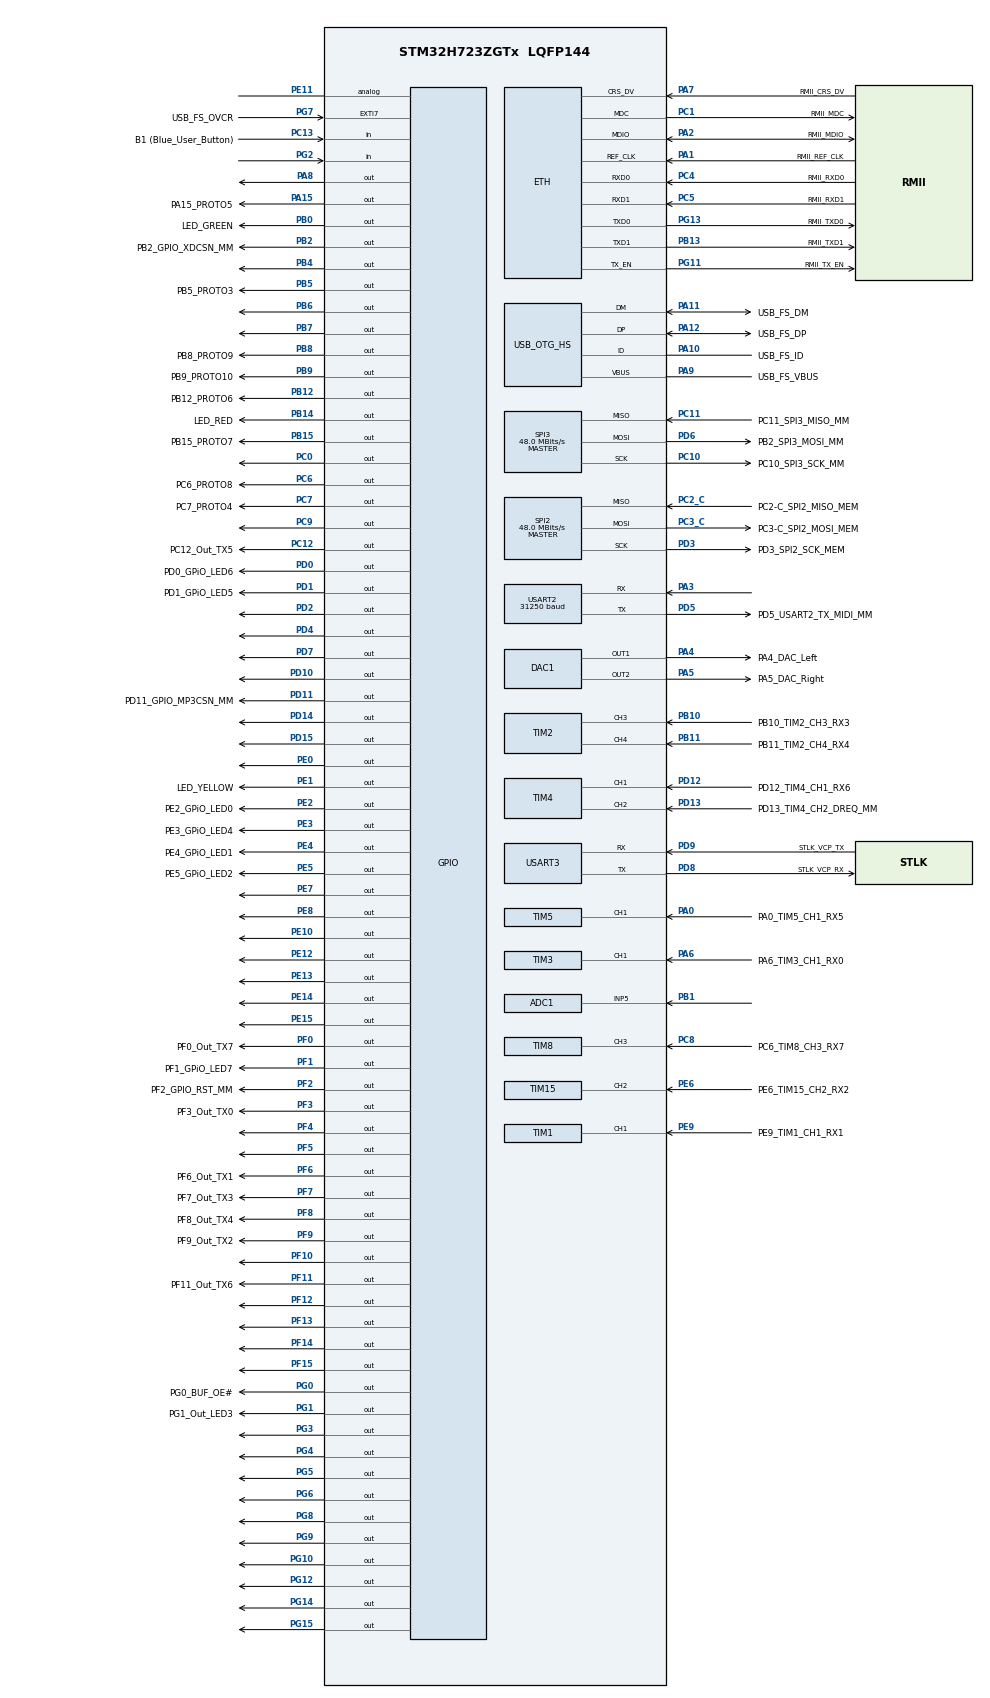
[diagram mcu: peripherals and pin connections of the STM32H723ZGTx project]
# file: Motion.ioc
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ADC1.Channel-0\#ChannelRegularConversion=ADC_CHANNEL_5
ADC1.NbrOfConversionFlag=1
ADC1.OffsetNumber-0\#ChannelRegularConversion=ADC_OFFSET_NONE
ADC1.OffsetSignedSaturation-0\#ChannelRegularConversion=DISABLE
ADC1.Rank-0\#ChannelRegularConversion=1
ADC1.SamplingTime-0\#ChannelRegularConversion=ADC_SAMPLETIME_1CYCLE_5
ADC1.master=1
DAC1.DAC_Channel-DAC_OUT1=DAC_CHANNEL_1
DAC1.DAC_Channel-DAC_OUT2=DAC_CHANNEL_2
DAC1.DAC_Trigger-DAC_OUT1=DAC_TRIGGER_T6_TRGO
DAC1.DAC_Trigger-DAC_OUT2=DAC_TRIGGER_T6_TRGO
Dma.DAC1_CH1.0.Direction=DMA_MEMORY_TO_PERIPH
Dma.DAC1_CH1.0.EventEnable=DISABLE
Dma.DAC1_CH1.0.FIFOMode=DMA_FIFOMODE_ENABLE
Dma.DAC1_CH1.0.FIFOThreshold=DMA_FIFO_THRESHOLD_FULL
Dma.DAC1_CH1.0.Instance=DMA1_Stream0
Dma.DAC1_CH1.0.MemBurst=DMA_MBURST_SINGLE
Dma.DAC1_CH1.0.MemDataAlignment=DMA_MDATAALIGN_HALFWORD
Dma.DAC1_CH1.0.MemInc=DMA_MINC_ENABLE
Dma.DAC1_CH1.0.Mode=DMA_CIRCULAR
Dma.DAC1_CH1.0.PeriphBurst=DMA_PBURST_SINGLE
Dma.DAC1_CH1.0.PeriphDataAlignment=DMA_PDATAALIGN_HALFWORD
Dma.DAC1_CH1.0.PeriphInc=DMA_PINC_DISABLE
Dma.DAC1_CH1.0.Polarity=HAL_DMAMUX_REQ_GEN_RISING
Dma.DAC1_CH1.0.Priority=DMA_PRIORITY_LOW
Dma.DAC1_CH1.0.RequestNumber=1
Dma.DAC1_CH1.0.SignalID=NONE
Dma.DAC1_CH1.0.SyncEnable=DISABLE
Dma.DAC1_CH1.0.SyncPolarity=HAL_DMAMUX_SYNC_NO_EVENT
Dma.DAC1_CH1.0.SyncRequestNumber=1
Dma.DAC1_CH1.0.SyncSignalID=NONE
Dma.DAC1_CH2.1.Direction=DMA_MEMORY_TO_PERIPH
Dma.DAC1_CH2.1.EventEnable=DISABLE
Dma.DAC1_CH2.1.FIFOMode=DMA_FIFOMODE_ENABLE
Dma.DAC1_CH2.1.FIFOThreshold=DMA_FIFO_THRESHOLD_FULL
Dma.DAC1_CH2.1.Instance=DMA1_Stream1
Dma.DAC1_CH2.1.MemBurst=DMA_MBURST_SINGLE
Dma.DAC1_CH2.1.MemDataAlignment=DMA_MDATAALIGN_HALFWORD
Dma.DAC1_CH2.1.MemInc=DMA_MINC_ENABLE
Dma.DAC1_CH2.1.Mode=DMA_NORMAL
Dma.DAC1_CH2.1.PeriphBurst=DMA_PBURST_SINGLE
Dma.DAC1_CH2.1.PeriphDataAlignment=DMA_PDATAALIGN_HALFWORD
Dma.DAC1_CH2.1.PeriphInc=DMA_PINC_DISABLE
Dma.DAC1_CH2.1.Polarity=HAL_DMAMUX_REQ_GEN_RISING
Dma.DAC1_CH2.1.Priority=DMA_PRIORITY_LOW
Dma.DAC1_CH2.1.RequestNumber=1
Dma.DAC1_CH2.1.SignalID=NONE
Dma.DAC1_CH2.1.SyncEnable=DISABLE
Dma.DAC1_CH2.1.SyncPolarity=HAL_DMAMUX_SYNC_NO_EVENT
Dma.DAC1_CH2.1.SyncRequestNumber=1
Dma.DAC1_CH2.1.SyncSignalID=NONE
Dma.Request0=DAC1_CH1
Dma.Request1=DAC1_CH2
ETH.MediaInterface=HAL_ETH_RMII_MODE
Mcu.Family=STM32H7
Mcu.Name=STM32H723ZGTx
Mcu.Package=LQFP144
NVIC.DMA1_Stream0_IRQn=true\:0\:0\:false\:false\:true\:false\:true\:true
NVIC.DMA1_Stream1_IRQn=true\:0\:0\:false\:false\:true\:false\:true\:true
NVIC.PriorityGroup=NVIC_PRIORITYGROUP_4
NVIC.TIM6_DAC_IRQn=true\:0\:0\:false\:false\:true\:true\:true\:true
NVIC.TIM8_BRK_TIM12_IRQn=true\:15\:0\:false\:false\:true\:false\:true\:true
NVIC.TimeBase=TIM8_BRK_TIM12_IRQn
NVIC.TimeBaseIP=TIM12
PA0.GPIO_Label=PA0_TIM5_CH1_RX5
PA0.Signal=S_TIM5_CH1
PA1.GPIO_Label=RMII_REF_CLK
PA1.Mode=RMII
PA1.Signal=ETH_REF_CLK
PA10.GPIO_Label=USB_FS_ID
PA10.Mode=OTG/Dual-Role-Device-FS
PA10.Signal=USB_OTG_HS_ID
PA11.GPIO_Label=USB_FS_DM
PA11.Mode=OTG/Dual-Role-Device-FS
PA11.Signal=USB_OTG_HS_DM
PA12.GPIO_Label=USB_FS_DP
PA12.Mode=OTG/Dual-Role-Device-FS
PA12.Signal=USB_OTG_HS_DP
PA13(JTMS/SWDIO).GPIO_Label=SWDIO
PA13(JTMS/SWDIO).Mode=Trace_Asynchronous_SW
PA13(JTMS/SWDIO).Signal=DEBUG_JTMS-SWDIO
PA14(JTCK/SWCLK).GPIO_Label=SWCLK
PA14(JTCK/SWCLK).Mode=Trace_Asynchronous_SW
PA14(JTCK/SWCLK).Signal=DEBUG_JTCK-SWCLK
PA15(JTDI).GPIO_Label=PA15_PROTO5
PA15(JTDI).Signal=GPIO_Output
PA2.GPIO_Label=RMII_MDIO
PA2.Mode=RMII
PA2.Signal=ETH_MDIO
PA3.Mode=Asynchronous
PA3.Signal=USART2_RX
PA4.GPIO_Label=PA4_DAC_Left
PA4.Signal=COMP_DAC11_group
PA5.GPIO_Label=PA5_DAC_Right
PA5.Signal=COMP_DAC12_group
PA6.GPIO_Label=PA6_TIM3_CH1_RX0
PA6.Signal=S_TIM3_CH1
PA7.GPIO_Label=RMII_CRS_DV
PA7.Mode=RMII
PA7.Signal=ETH_CRS_DV
PA8.Signal=GPIO_Output
PA9.GPIO_Label=USB_FS_VBUS
PA9.Mode=Activate_VBUS_FS
PA9.Signal=USB_OTG_HS_VBUS
PB0.GPIO_Label=LED_GREEN
PB0.Signal=GPIO_Output
PB1.Signal=ADCx_INP5
PB10.GPIO_Label=PB10_TIM2_CH3_RX3
PB10.Signal=S_TIM2_CH3
PB11.GPIO_Label=PB11_TIM2_CH4_RX4
PB11.Signal=S_TIM2_CH4
PB12.GPIO_Label=PB12_PROTO6
PB12.Signal=GPIO_Output
PB13.GPIO_Label=RMII_TXD1
PB13.Mode=RMII
PB13.Signal=ETH_TXD1
PB14.GPIO_Label=LED_RED
PB14.Signal=GPIO_Output
PB15.GPIO_Label=PB15_PROTO7
PB15.Signal=GPIO_Output
PB2.GPIO_Label=PB2_GPIO_XDCSN_MM
PB2.Signal=GPIO_Output
PB3(JTDO/TRACESWO).GPIO_Label=SWO
PB3(JTDO/TRACESWO).Mode=Trace_Asynchronous_SW
PB3(JTDO/TRACESWO).Signal=DEBUG_JTDO-SWO
PB4(NJTRST).Signal=GPIO_Output
PB5.GPIO_Label=PB5_PROTO3
PB5.Signal=GPIO_Output
PB6.Signal=GPIO_Output
PB7.Signal=GPIO_Output
PB8.GPIO_Label=PB8_PROTO9
PB8.Signal=GPIO_Output
PB9.GPIO_Label=PB9_PROTO10
PB9.Signal=GPIO_Output
PC0.Signal=GPIO_Output
PC1.GPIO_Label=RMII_MDC
PC1.Mode=RMII
PC1.Signal=ETH_MDC
PC10.GPIO_Label=PC10_SPI3_SCK_MM
PC10.Mode=Full_Duplex_Master
PC10.Signal=SPI3_SCK
PC11.GPIO_Label=PC11_SPI3_MISO_MM
PC11.Mode=Full_Duplex_Master
PC11.Signal=SPI3_MISO
PC12.GPIO_Label=PC12_Out_TX5
PC12.Signal=GPIO_Output
PC13.GPIO_Label=B1 (Blue_User_Button)
PC13.Signal=GPIO_Input
PC14-OSC32_IN.Mode=LSE-External-Oscillator
PC14-OSC32_IN.Signal=RCC_OSC32_IN
PC15-OSC32_OUT.Mode=LSE-External-Oscillator
PC15-OSC32_OUT.Signal=RCC_OSC32_OUT
PC2_C.GPIO_Label=PC2-C_SPI2_MISO_MEM
PC2_C.Mode=Full_Duplex_Master
PC2_C.Signal=SPI2_MISO
PC3_C.GPIO_Label=PC3-C_SPI2_MOSI_MEM
PC3_C.Mode=Full_Duplex_Master
PC3_C.Signal=SPI2_MOSI
PC4.GPIO_Label=RMII_RXD0
PC4.Mode=RMII
PC4.Signal=ETH_RXD0
PC5.GPIO_Label=RMII_RXD1
PC5.Mode=RMII
PC5.Signal=ETH_RXD1
PC6.GPIO_Label=PC6_PROTO8
PC6.Signal=GPIO_Output
PC7.GPIO_Label=PC7_PROTO4
PC7.Signal=GPIO_Output
PC8.GPIO_Label=PC6_TIM8_CH3_RX7
PC8.Signal=S_TIM8_CH3
PC9.Signal=GPIO_Output
PD0.GPIO_Label=PD0_GPiO_LED6
PD0.Signal=GPIO_Output
PD1.GPIO_Label=PD1_GPiO_LED5
PD1.Signal=GPIO_Output
PD10.Signal=GPIO_Output
PD11.GPIO_Label=PD11_GPIO_MP3CSN_MM
PD11.Signal=GPIO_Output
PD12.GPIO_Label=PD12_TIM4_CH1_RX6
PD12.Signal=S_TIM4_CH1
PD13.GPIO_Label=PD13_TIM4_CH2_DREQ_MM
PD13.Signal=S_TIM4_CH2
PD14.Signal=GPIO_Output
PD15.Signal=GPIO_Output
PD2.Signal=GPIO_Output
PD3.GPIO_Label=PD3_SPI2_SCK_MEM
PD3.Mode=Full_Duplex_Master
PD3.Signal=SPI2_SCK
PD4.Signal=GPIO_Output
PD5.GPIO_Label=PD5_USART2_TX_MIDI_MM
PD5.Mode=Asynchronous
PD5.Signal=USART2_TX
PD6.GPIO_Label=PB2_SPI3_MOSI_MM
PD6.Mode=Full_Duplex_Master
PD6.Signal=SPI3_MOSI
PD7.Signal=GPIO_Output
PD8.GPIO_Label=STLK_VCP_RX
PD8.Mode=Asynchronous
PD8.Signal=USART3_TX
PD9.GPIO_Label=STLK_VCP_TX
PD9.Mode=Asynchronous
PD9.Signal=USART3_RX
PE0.Signal=GPIO_Output
PE1.GPIO_Label=LED_YELLOW
PE1.Signal=GPIO_Output
PE10.Signal=GPIO_Output
PE11.Signal=GPIO_Analog
PE12.Signal=GPIO_Output
PE13.Signal=GPIO_Output
PE14.Signal=GPIO_Output
PE15.Signal=GPIO_Output
PE2.GPIO_Label=PE2_GPiO_LED0
PE2.Signal=GPIO_Output
PE3.GPIO_Label=PE3_GPiO_LED4
PE3.Signal=GPIO_Output
PE4.GPIO_Label=PE4_GPiO_LED1
PE4.Signal=GPIO_Output
PE5.GPIO_Label=PE5_GPiO_LED2
PE5.Signal=GPIO_Output
PE6.GPIO_Label=PE6_TIM15_CH2_RX2
PE6.Signal=S_TIM15_CH2
PE7.Signal=GPIO_Output
PE8.Signal=GPIO_Output
PE9.GPIO_Label=PE9_TIM1_CH1_RX1
PE9.Signal=S_TIM1_CH1
PF0.GPIO_Label=PF0_Out_TX7
PF0.Signal=GPIO_Output
PF1.GPIO_Label=PF1_GPiO_LED7
PF1.Signal=GPIO_Output
PF10.Signal=GPIO_Output
PF11.GPIO_Label=PF11_Out_TX6
PF11.Signal=GPIO_Output
PF12.Signal=GPIO_Output
PF13.Signal=GPIO_Output
PF14.Signal=GPIO_Output
PF15.Signal=GPIO_Output
PF2.GPIO_Label=PF2_GPIO_RST_MM
PF2.Signal=GPIO_Output
PF3.GPIO_Label=PF3_Out_TX0
PF3.Signal=GPIO_Output
PF4.Signal=GPIO_Output
PF5.Signal=GPIO_Output
PF6.GPIO_Label=PF6_Out_TX1
PF6.Signal=GPIO_Output
PF7.GPIO_Label=PF7_Out_TX3
PF7.Signal=GPIO_Output
PF8.GPIO_Label=PF8_Out_TX4
PF8.Signal=GPIO_Output
PF9.GPIO_Label=PF9_Out_TX2
PF9.Signal=GPIO_Output
PG0.GPIO_Label=PG0_BUF_OE\#
PG0.Signal=GPIO_Output
PG1.GPIO_Label=PG1_Out_LED3
PG1.Signal=GPIO_Output
PG10.Signal=GPIO_Output
PG11.GPIO_Label=RMII_TX_EN
PG11.Mode=RMII
PG11.Signal=ETH_TX_EN
PG12.Signal=GPIO_Output
PG13.GPIO_Label=RMII_TXD0
PG13.Mode=RMII
PG13.Signal=ETH_TXD0
PG14.Signal=GPIO_Output
PG15.Signal=GPIO_Output
PG2.Signal=GPIO_Input
PG3.Signal=GPIO_Output
PG4.Signal=GPIO_Output
PG5.Signal=GPIO_Output
PG6.Signal=GPIO_Output
PG7.GPIO_Label=USB_FS_OVCR
PG7.Signal=GPXTI7
PG8.Signal=GPIO_Output
PG9.Signal=GPIO_Output
PH0-OSC_IN.GPIO_Label=MCO
PH0-OSC_IN.Mode=HSE-External-Clock-Source
PH0-OSC_IN.Signal=RCC_OSC_IN
PH1-OSC_OUT.Signal=RCC_OSC_OUT
ProjectManager.HeapSize=0x200
ProjectManager.StackSize=0x400
ProjectManager.TargetToolchain=STM32CubeIDE
RCC.ADCFreq_Value=48000000
RCC.APB1Freq_Value=48000000
RCC.APB2Freq_Value=48000000
RCC.APB3Freq_Value=48000000
RCC.APB4Freq_Value=48000000
RCC.CortexFreq_Value=192000000
RCC.D1PPRE=RCC_APB3_DIV2
RCC.D2PPRE1=RCC_APB1_DIV2
RCC.D2PPRE2=RCC_APB2_DIV2
RCC.D3PPRE=RCC_APB4_DIV2
RCC.DIVM1=1
RCC.DIVM2=1
RCC.DIVN1=24
RCC.DIVN2=24
RCC.DIVP1=1
RCC.DIVP2=4
RCC.HCLKFreq_Value=96000000
RCC.HPRE=RCC_HCLK_DIV2
RCC.HSE_VALUE=8000000
RCC.PLL2FRACN=0
RCC.PLLFRACN=0
RCC.PLLSourceVirtual=RCC_PLLSOURCE_HSE
RCC.SYSCLKFreq_VALUE=192000000
RCC.SYSCLKSource=RCC_SYSCLKSOURCE_PLLCLK
RCC.USBCLockSelection=RCC_USBCLKSOURCE_HSI48
RCC.USBFreq_Value=48000000
SH.ADCx_INP5.0=ADC1_INP5,IN5-Single-Ended
SH.COMP_DAC11_group.0=DAC1_OUT1,DAC_OUT1
SH.COMP_DAC12_group.0=DAC1_OUT2,DAC_OUT2
SH.S_TIM15_CH2.0=TIM15_CH2,Input_Capture2_from_TI2
SH.S_TIM1_CH1.0=TIM1_CH1,Input_Capture1_from_TI1
SH.S_TIM2_CH3.0=TIM2_CH3,Input_Capture3_from_TI3
SH.S_TIM2_CH4.0=TIM2_CH4,Input_Capture4_from_TI4
SH.S_TIM3_CH1.0=TIM3_CH1,Input_Capture1_from_TI1
SH.S_TIM4_CH1.0=TIM4_CH1,Input_Capture1_from_TI1
SH.S_TIM4_CH2.0=TIM4_CH2,Input_Capture2_from_TI2
SH.S_TIM5_CH1.0=TIM5_CH1,Input_Capture1_from_TI1
SH.S_TIM8_CH3.0=TIM8_CH3,Input_Capture3_from_TI3
SPI2.CalculateBaudRate=48.0 MBits/s
SPI2.Direction=SPI_DIRECTION_2LINES
SPI2.Mode=SPI_MODE_MASTER
SPI2.VirtualType=VM_MASTER
SPI3.CalculateBaudRate=48.0 MBits/s
SPI3.Direction=SPI_DIRECTION_2LINES
SPI3.Mode=SPI_MODE_MASTER
SPI3.VirtualType=VM_MASTER
TIM1.Channel-Input_Capture1_from_TI1=TIM_CHANNEL_1
TIM15.Channel-Input_Capture2_from_TI2=TIM_CHANNEL_2
TIM2.Channel-Input_Capture3_from_TI3=TIM_CHANNEL_3
TIM2.Channel-Input_Capture4_from_TI4=TIM_CHANNEL_4
TIM3.Channel-Input_Capture1_from_TI1=TIM_CHANNEL_1
TIM4.Channel-Input_Capture1_from_TI1=TIM_CHANNEL_1
TIM4.Channel-Input_Capture2_from_TI2=TIM_CHANNEL_2
TIM5.Channel-Input_Capture1_from_TI1=TIM_CHANNEL_1
TIM6.Period=16
TIM6.Prescaler=32
TIM6.TIM_MasterOutputTrigger=TIM_TRGO_UPDATE
TIM8.Channel-Input_Capture3_from_TI3=TIM_CHANNEL_3
USART2.BaudRate=31250
USART2.VirtualMode-Asynchronous=VM_ASYNC
USART3.VirtualMode-Asynchronous=VM_ASYNC
VP_RNG_VS_RNG.Mode=RNG_Activate
VP_SYS_VS_tim12.Mode=TIM12
VP_TIM13_VS_ClockSourceINT.Mode=Enable_Timer
VP_TIM14_VS_ClockSourceINT.Mode=Enable_Timer
VP_TIM16_VS_ClockSourceINT.Mode=Enable_Timer
VP_TIM17_VS_ClockSourceINT.Mode=Enable_Timer
VP_TIM1_VS_ClockSourceINT.Mode=Internal
VP_TIM2_VS_ClockSourceINT.Mode=Internal
VP_TIM3_VS_ClockSourceINT.Mode=Internal
VP_TIM4_VS_ClockSourceINT.Mode=Internal
VP_TIM5_VS_ClockSourceINT.Mode=Internal
VP_TIM6_VS_ClockSourceINT.Mode=Enable_Timer
board=NUCLEO-H723ZG

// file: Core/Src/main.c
/* USER CODE BEGIN Header */
/**
  ******************************************************************************
  * @file           : main.c
  * @brief          : Main program body
  ******************************************************************************
  * @attention
  *
  * Copyright (c) 2021 STMicroelectronics.
  * All rights reserved.
  *
  * This software is licensed under terms that can be found in the LICENSE file
  * in the root directory of this software component.
  * If no LICENSE file comes with this software, it is provided AS-IS.
  *
  ******************************************************************************
  */
/* USER CODE END Header */
#include "main.h"
#include "string.h"

/* USER CODE BEGIN Includes */
#include <stdbool.h>
#include "AppMain.h"

/* USER CODE END Includes */

#if defined ( __ICCARM__ ) /*!< IAR Compiler */
#pragma location=0x30000000
ETH_DMADescTypeDef  DMARxDscrTab[ETH_RX_DESC_CNT]; /* Ethernet Rx DMA Descriptors */
#pragma location=0x30000200
ETH_DMADescTypeDef  DMATxDscrTab[ETH_TX_DESC_CNT]; /* Ethernet Tx DMA Descriptors */

#elif defined ( __CC_ARM )  /* MDK ARM Compiler */

__attribute__((at(0x30000000))) ETH_DMADescTypeDef  DMARxDscrTab[ETH_RX_DESC_CNT]; /* Ethernet Rx DMA Descriptors */
__attribute__((at(0x30000200))) ETH_DMADescTypeDef  DMATxDscrTab[ETH_TX_DESC_CNT]; /* Ethernet Tx DMA Descriptors */

#elif defined ( __GNUC__ ) /* GNU Compiler */
ETH_DMADescTypeDef DMARxDscrTab[ETH_RX_DESC_CNT] __attribute__((section(".RxDecripSection"))); /* Ethernet Rx DMA Descriptors */
ETH_DMADescTypeDef DMATxDscrTab[ETH_TX_DESC_CNT] __attribute__((section(".TxDecripSection")));   /* Ethernet Tx DMA Descriptors */

#endif

ETH_TxPacketConfig TxConfig;

ADC_HandleTypeDef hadc1;

DAC_HandleTypeDef hdac1;
DMA_HandleTypeDef hdma_dac1_ch1;
DMA_HandleTypeDef hdma_dac1_ch2;

ETH_HandleTypeDef heth;

RNG_HandleTypeDef hrng;

SPI_HandleTypeDef hspi2;
SPI_HandleTypeDef hspi3;

TIM_HandleTypeDef htim1;
TIM_HandleTypeDef htim2;
TIM_HandleTypeDef htim3;
TIM_HandleTypeDef htim4;
TIM_HandleTypeDef htim5;
TIM_HandleTypeDef htim6;
TIM_HandleTypeDef htim8;
TIM_HandleTypeDef htim13;
TIM_HandleTypeDef htim14;
TIM_HandleTypeDef htim15;
TIM_HandleTypeDef htim16;
TIM_HandleTypeDef htim17;

UART_HandleTypeDef huart2;
UART_HandleTypeDef huart3;

void SystemClock_Config(void);
static void MX_GPIO_Init(void);
static void MX_DMA_Init(void);
static void MX_TIM1_Init(void);
static void MX_TIM2_Init(void);
static void MX_TIM3_Init(void);
static void MX_TIM4_Init(void);
static void MX_TIM5_Init(void);
static void MX_TIM13_Init(void);
static void MX_TIM14_Init(void);
static void MX_TIM17_Init(void);
static void MX_USART3_UART_Init(void);
static void MX_USB_OTG_HS_USB_Init(void);
static void MX_TIM16_Init(void);
static void MX_DAC1_Init(void);
static void MX_TIM8_Init(void);
static void MX_SPI2_Init(void);
static void MX_SPI3_Init(void);
static void MX_USART2_UART_Init(void);
static void MX_ETH_Init(void);
static void MX_TIM6_Init(void);
static void MX_ADC1_Init(void);
static void MX_TIM15_Init(void);
static void MX_RNG_Init(void);

int main(void)
{

  /* MCU Configuration--------------------------------------------------------*/

  /* Reset of all peripherals, Initializes the Flash interface and the Systick. */
  HAL_Init();

  /* Configure the system clock */
  SystemClock_Config();

  /* Initialize all configured peripherals */
  MX_GPIO_Init();
  MX_DMA_Init();
  MX_TIM1_Init();
  MX_TIM2_Init();
  MX_TIM3_Init();
  MX_TIM4_Init();
  MX_TIM5_Init();
  MX_TIM13_Init();
  MX_TIM14_Init();
  MX_TIM17_Init();
  MX_USART3_UART_Init();
  MX_USB_OTG_HS_USB_Init();
  MX_TIM16_Init();
  MX_DAC1_Init();
  MX_TIM8_Init();
  MX_SPI2_Init();
  MX_SPI3_Init();
  MX_USART2_UART_Init();
  MX_ETH_Init();
  MX_TIM6_Init();
  MX_ADC1_Init();
  MX_TIM15_Init();
  MX_RNG_Init();
  /* USER CODE BEGIN 2 */
  return AppMain();
  /* USER CODE END 2 */

  /* Infinite loop */
  while (1)
  {

  }
}

void SystemClock_Config(void)
{
  RCC_OscInitTypeDef RCC_OscInitStruct = {0};
  RCC_ClkInitTypeDef RCC_ClkInitStruct = {0};

  /** Supply configuration update enable
  */
  HAL_PWREx_ConfigSupply(PWR_LDO_SUPPLY);

  /** Configure the main internal regulator output voltage
  */
  __HAL_PWR_VOLTAGESCALING_CONFIG(PWR_REGULATOR_VOLTAGE_SCALE2);

  while(!__HAL_PWR_GET_FLAG(PWR_FLAG_VOSRDY)) {}

  /** Macro to configure the PLL clock source
  */
  __HAL_RCC_PLL_PLLSOURCE_CONFIG(RCC_PLLSOURCE_HSE);

  /** Initializes the RCC Oscillators according to the specified parameters
  * in the RCC_OscInitTypeDef structure.
  */
  RCC_OscInitStruct.OscillatorType = RCC_OSCILLATORTYPE_HSI48|RCC_OSCILLATORTYPE_HSE;
  RCC_OscInitStruct.HSEState = RCC_HSE_BYPASS;
  RCC_OscInitStruct.HSI48State = RCC_HSI48_ON;
  RCC_OscInitStruct.PLL.PLLState = RCC_PLL_ON;
  RCC_OscInitStruct.PLL.PLLSource = RCC_PLLSOURCE_HSE;
  RCC_OscInitStruct.PLL.PLLM = 1;
  RCC_OscInitStruct.PLL.PLLN = 24;
  RCC_OscInitStruct.PLL.PLLP = 1;
  RCC_OscInitStruct.PLL.PLLQ = 2;
  RCC_OscInitStruct.PLL.PLLR = 2;
  RCC_OscInitStruct.PLL.PLLRGE = RCC_PLL1VCIRANGE_3;
  RCC_OscInitStruct.PLL.PLLVCOSEL = RCC_PLL1VCOWIDE;
  RCC_OscInitStruct.PLL.PLLFRACN = 0;
  if (HAL_RCC_OscConfig(&RCC_OscInitStruct) != HAL_OK)
  {
    Error_Handler();
  }

  /** Initializes the CPU, AHB and APB buses clocks
  */
  RCC_ClkInitStruct.ClockType = RCC_CLOCKTYPE_HCLK|RCC_CLOCKTYPE_SYSCLK
                              |RCC_CLOCKTYPE_PCLK1|RCC_CLOCKTYPE_PCLK2
                              |RCC_CLOCKTYPE_D3PCLK1|RCC_CLOCKTYPE_D1PCLK1;
  RCC_ClkInitStruct.SYSCLKSource = RCC_SYSCLKSOURCE_PLLCLK;
  RCC_ClkInitStruct.SYSCLKDivider = RCC_SYSCLK_DIV1;
  RCC_ClkInitStruct.AHBCLKDivider = RCC_HCLK_DIV2;
  RCC_ClkInitStruct.APB3CLKDivider = RCC_APB3_DIV2;
  RCC_ClkInitStruct.APB1CLKDivider = RCC_APB1_DIV2;
  RCC_ClkInitStruct.APB2CLKDivider = RCC_APB2_DIV2;
  RCC_ClkInitStruct.APB4CLKDivider = RCC_APB4_DIV2;

  if (HAL_RCC_ClockConfig(&RCC_ClkInitStruct, FLASH_LATENCY_1) != HAL_OK)
  {
    Error_Handler();
  }
}

static void MX_ADC1_Init(void)
{

  ADC_MultiModeTypeDef multimode = {0};
  ADC_ChannelConfTypeDef sConfig = {0};

  /** Common config
  */
  hadc1.Instance = ADC1;
  hadc1.Init.ClockPrescaler = ADC_CLOCK_ASYNC_DIV4;
  hadc1.Init.Resolution = ADC_RESOLUTION_16B;
  hadc1.Init.ScanConvMode = ADC_SCAN_DISABLE;
  hadc1.Init.EOCSelection = ADC_EOC_SINGLE_CONV;
  hadc1.Init.LowPowerAutoWait = DISABLE;
  hadc1.Init.ContinuousConvMode = DISABLE;
  hadc1.Init.NbrOfConversion = 1;
  hadc1.Init.DiscontinuousConvMode = DISABLE;
  hadc1.Init.ExternalTrigConv = ADC_SOFTWARE_START;
  hadc1.Init.ExternalTrigConvEdge = ADC_EXTERNALTRIGCONVEDGE_NONE;
  hadc1.Init.ConversionDataManagement = ADC_CONVERSIONDATA_DR;
  hadc1.Init.Overrun = ADC_OVR_DATA_PRESERVED;
  hadc1.Init.LeftBitShift = ADC_LEFTBITSHIFT_NONE;
  hadc1.Init.OversamplingMode = DISABLE;
  if (HAL_ADC_Init(&hadc1) != HAL_OK)
  {
    Error_Handler();
  }

  /** Configure the ADC multi-mode
  */
  multimode.Mode = ADC_MODE_INDEPENDENT;
  if (HAL_ADCEx_MultiModeConfigChannel(&hadc1, &multimode) != HAL_OK)
  {
    Error_Handler();
  }

  /** Configure Regular Channel
  */
  sConfig.Channel = ADC_CHANNEL_5;
  sConfig.Rank = ADC_REGULAR_RANK_1;
  sConfig.SamplingTime = ADC_SAMPLETIME_1CYCLE_5;
  sConfig.SingleDiff = ADC_SINGLE_ENDED;
  sConfig.OffsetNumber = ADC_OFFSET_NONE;
  sConfig.Offset = 0;
  sConfig.OffsetSignedSaturation = DISABLE;
  if (HAL_ADC_ConfigChannel(&hadc1, &sConfig) != HAL_OK)
  {
    Error_Handler();
  }

}

static void MX_DAC1_Init(void)
{

  DAC_ChannelConfTypeDef sConfig = {0};

  /** DAC Initialization
  */
  hdac1.Instance = DAC1;
  if (HAL_DAC_Init(&hdac1) != HAL_OK)
  {
    Error_Handler();
  }

  /** DAC channel OUT1 config
  */
  sConfig.DAC_SampleAndHold = DAC_SAMPLEANDHOLD_DISABLE;
  sConfig.DAC_Trigger = DAC_TRIGGER_T6_TRGO;
  sConfig.DAC_OutputBuffer = DAC_OUTPUTBUFFER_ENABLE;
  sConfig.DAC_ConnectOnChipPeripheral = DAC_CHIPCONNECT_DISABLE;
  sConfig.DAC_UserTrimming = DAC_TRIMMING_FACTORY;
  if (HAL_DAC_ConfigChannel(&hdac1, &sConfig, DAC_CHANNEL_1) != HAL_OK)
  {
    Error_Handler();
  }

  /** DAC channel OUT2 config
  */
  if (HAL_DAC_ConfigChannel(&hdac1, &sConfig, DAC_CHANNEL_2) != HAL_OK)
  {
    Error_Handler();
  }

}

static void MX_ETH_Init(void)
{

   static uint8_t MACAddr[6];

  heth.Instance = ETH;
  MACAddr[0] = 0x00;
  MACAddr[1] = 0x80;
  MACAddr[2] = 0xE1;
  MACAddr[3] = 0x00;
  MACAddr[4] = 0x00;
  MACAddr[5] = 0x00;
  heth.Init.MACAddr = &MACAddr[0];
  heth.Init.MediaInterface = HAL_ETH_RMII_MODE;
  heth.Init.TxDesc = DMATxDscrTab;
  heth.Init.RxDesc = DMARxDscrTab;
  heth.Init.RxBuffLen = 1524;

  if (HAL_ETH_Init(&heth) != HAL_OK)
  {
    Error_Handler();
  }

  memset(&TxConfig, 0 , sizeof(ETH_TxPacketConfig));
  TxConfig.Attributes = ETH_TX_PACKETS_FEATURES_CSUM | ETH_TX_PACKETS_FEATURES_CRCPAD;
  TxConfig.ChecksumCtrl = ETH_CHECKSUM_IPHDR_PAYLOAD_INSERT_PHDR_CALC;
  TxConfig.CRCPadCtrl = ETH_CRC_PAD_INSERT;

}

static void MX_RNG_Init(void)
{

  hrng.Instance = RNG;
  hrng.Init.ClockErrorDetection = RNG_CED_ENABLE;
  if (HAL_RNG_Init(&hrng) != HAL_OK)
  {
    Error_Handler();
  }

}

static void MX_SPI2_Init(void)
{

  /* SPI2 parameter configuration*/
  hspi2.Instance = SPI2;
  hspi2.Init.Mode = SPI_MODE_MASTER;
  hspi2.Init.Direction = SPI_DIRECTION_2LINES;
  hspi2.Init.DataSize = SPI_DATASIZE_4BIT;
  hspi2.Init.CLKPolarity = SPI_POLARITY_LOW;
  hspi2.Init.CLKPhase = SPI_PHASE_1EDGE;
  hspi2.Init.NSS = SPI_NSS_SOFT;
  hspi2.Init.BaudRatePrescaler = SPI_BAUDRATEPRESCALER_2;
  hspi2.Init.FirstBit = SPI_FIRSTBIT_MSB;
  hspi2.Init.TIMode = SPI_TIMODE_DISABLE;
  hspi2.Init.CRCCalculation = SPI_CRCCALCULATION_DISABLE;
  hspi2.Init.CRCPolynomial = 0x0;
  hspi2.Init.NSSPMode = SPI_NSS_PULSE_ENABLE;
  hspi2.Init.NSSPolarity = SPI_NSS_POLARITY_LOW;
  hspi2.Init.FifoThreshold = SPI_FIFO_THRESHOLD_01DATA;
  hspi2.Init.TxCRCInitializationPattern = SPI_CRC_INITIALIZATION_ALL_ZERO_PATTERN;
  hspi2.Init.RxCRCInitializationPattern = SPI_CRC_INITIALIZATION_ALL_ZERO_PATTERN;
  hspi2.Init.MasterSSIdleness = SPI_MASTER_SS_IDLENESS_00CYCLE;
  hspi2.Init.MasterInterDataIdleness = SPI_MASTER_INTERDATA_IDLENESS_00CYCLE;
  hspi2.Init.MasterReceiverAutoSusp = SPI_MASTER_RX_AUTOSUSP_DISABLE;
  hspi2.Init.MasterKeepIOState = SPI_MASTER_KEEP_IO_STATE_DISABLE;
  hspi2.Init.IOSwap = SPI_IO_SWAP_DISABLE;
  if (HAL_SPI_Init(&hspi2) != HAL_OK)
  {
    Error_Handler();
  }

}

static void MX_SPI3_Init(void)
{

  /* SPI3 parameter configuration*/
  hspi3.Instance = SPI3;
  hspi3.Init.Mode = SPI_MODE_MASTER;
  hspi3.Init.Direction = SPI_DIRECTION_2LINES;
  hspi3.Init.DataSize = SPI_DATASIZE_4BIT;
  hspi3.Init.CLKPolarity = SPI_POLARITY_LOW;
  hspi3.Init.CLKPhase = SPI_PHASE_1EDGE;
  hspi3.Init.NSS = SPI_NSS_SOFT;
  hspi3.Init.BaudRatePrescaler = SPI_BAUDRATEPRESCALER_2;
  hspi3.Init.FirstBit = SPI_FIRSTBIT_MSB;
  hspi3.Init.TIMode = SPI_TIMODE_DISABLE;
  hspi3.Init.CRCCalculation = SPI_CRCCALCULATION_DISABLE;
  hspi3.Init.CRCPolynomial = 0x0;
  hspi3.Init.NSSPMode = SPI_NSS_PULSE_ENABLE;
  hspi3.Init.NSSPolarity = SPI_NSS_POLARITY_LOW;
  hspi3.Init.FifoThreshold = SPI_FIFO_THRESHOLD_01DATA;
  hspi3.Init.TxCRCInitializationPattern = SPI_CRC_INITIALIZATION_ALL_ZERO_PATTERN;
  hspi3.Init.RxCRCInitializationPattern = SPI_CRC_INITIALIZATION_ALL_ZERO_PATTERN;
  hspi3.Init.MasterSSIdleness = SPI_MASTER_SS_IDLENESS_00CYCLE;
  hspi3.Init.MasterInterDataIdleness = SPI_MASTER_INTERDATA_IDLENESS_00CYCLE;
  hspi3.Init.MasterReceiverAutoSusp = SPI_MASTER_RX_AUTOSUSP_DISABLE;
  hspi3.Init.MasterKeepIOState = SPI_MASTER_KEEP_IO_STATE_DISABLE;
  hspi3.Init.IOSwap = SPI_IO_SWAP_DISABLE;
  if (HAL_SPI_Init(&hspi3) != HAL_OK)
  {
    Error_Handler();
  }

}

static void MX_TIM1_Init(void)
{

  TIM_ClockConfigTypeDef sClockSourceConfig = {0};
  TIM_MasterConfigTypeDef sMasterConfig = {0};
  TIM_IC_InitTypeDef sConfigIC = {0};

  htim1.Instance = TIM1;
  htim1.Init.Prescaler = 0;
  htim1.Init.CounterMode = TIM_COUNTERMODE_UP;
  htim1.Init.Period = 65535;
  htim1.Init.ClockDivision = TIM_CLOCKDIVISION_DIV1;
  htim1.Init.RepetitionCounter = 0;
  htim1.Init.AutoReloadPreload = TIM_AUTORELOAD_PRELOAD_DISABLE;
  if (HAL_TIM_Base_Init(&htim1) != HAL_OK)
  {
    Error_Handler();
  }
  sClockSourceConfig.ClockSource = TIM_CLOCKSOURCE_INTERNAL;
  if (HAL_TIM_ConfigClockSource(&htim1, &sClockSourceConfig) != HAL_OK)
  {
    Error_Handler();
  }
  if (HAL_TIM_IC_Init(&htim1) != HAL_OK)
  {
    Error_Handler();
  }
  sMasterConfig.MasterOutputTrigger = TIM_TRGO_RESET;
  sMasterConfig.MasterOutputTrigger2 = TIM_TRGO2_RESET;
  sMasterConfig.MasterSlaveMode = TIM_MASTERSLAVEMODE_DISABLE;
  if (HAL_TIMEx_MasterConfigSynchronization(&htim1, &sMasterConfig) != HAL_OK)
  {
    Error_Handler();
  }
  sConfigIC.ICPolarity = TIM_INPUTCHANNELPOLARITY_RISING;
  sConfigIC.ICSelection = TIM_ICSELECTION_DIRECTTI;
  sConfigIC.ICPrescaler = TIM_ICPSC_DIV1;
  sConfigIC.ICFilter = 0;
  if (HAL_TIM_IC_ConfigChannel(&htim1, &sConfigIC, TIM_CHANNEL_1) != HAL_OK)
  {
    Error_Handler();
  }

}

static void MX_TIM2_Init(void)
{

  TIM_ClockConfigTypeDef sClockSourceConfig = {0};
  TIM_MasterConfigTypeDef sMasterConfig = {0};
  TIM_IC_InitTypeDef sConfigIC = {0};

  htim2.Instance = TIM2;
  htim2.Init.Prescaler = 0;
  htim2.Init.CounterMode = TIM_COUNTERMODE_UP;
  htim2.Init.Period = 4294967295;
  htim2.Init.ClockDivision = TIM_CLOCKDIVISION_DIV1;
  htim2.Init.AutoReloadPreload = TIM_AUTORELOAD_PRELOAD_DISABLE;
  if (HAL_TIM_Base_Init(&htim2) != HAL_OK)
  {
    Error_Handler();
  }
  sClockSourceConfig.ClockSource = TIM_CLOCKSOURCE_INTERNAL;
  if (HAL_TIM_ConfigClockSource(&htim2, &sClockSourceConfig) != HAL_OK)
  {
    Error_Handler();
  }
  if (HAL_TIM_IC_Init(&htim2) != HAL_OK)
  {
    Error_Handler();
  }
  sMasterConfig.MasterOutputTrigger = TIM_TRGO_RESET;
  sMasterConfig.MasterSlaveMode = TIM_MASTERSLAVEMODE_DISABLE;
  if (HAL_TIMEx_MasterConfigSynchronization(&htim2, &sMasterConfig) != HAL_OK)
  {
    Error_Handler();
  }
  sConfigIC.ICPolarity = TIM_INPUTCHANNELPOLARITY_RISING;
  sConfigIC.ICSelection = TIM_ICSELECTION_DIRECTTI;
  sConfigIC.ICPrescaler = TIM_ICPSC_DIV1;
  sConfigIC.ICFilter = 0;
  if (HAL_TIM_IC_ConfigChannel(&htim2, &sConfigIC, TIM_CHANNEL_3) != HAL_OK)
  {
    Error_Handler();
  }
  if (HAL_TIM_IC_ConfigChannel(&htim2, &sConfigIC, TIM_CHANNEL_4) != HAL_OK)
  {
    Error_Handler();
  }

}

static void MX_TIM3_Init(void)
{

  TIM_ClockConfigTypeDef sClockSourceConfig = {0};
  TIM_MasterConfigTypeDef sMasterConfig = {0};
  TIM_IC_InitTypeDef sConfigIC = {0};

  htim3.Instance = TIM3;
  htim3.Init.Prescaler = 0;
  htim3.Init.CounterMode = TIM_COUNTERMODE_UP;
  htim3.Init.Period = 65535;
  htim3.Init.ClockDivision = TIM_CLOCKDIVISION_DIV1;
  htim3.Init.AutoReloadPreload = TIM_AUTORELOAD_PRELOAD_DISABLE;
  if (HAL_TIM_Base_Init(&htim3) != HAL_OK)
  {
    Error_Handler();
  }
  sClockSourceConfig.ClockSource = TIM_CLOCKSOURCE_INTERNAL;
  if (HAL_TIM_ConfigClockSource(&htim3, &sClockSourceConfig) != HAL_OK)
  {
    Error_Handler();
  }
  if (HAL_TIM_IC_Init(&htim3) != HAL_OK)
  {
    Error_Handler();
  }
  sMasterConfig.MasterOutputTrigger = TIM_TRGO_RESET;
  sMasterConfig.MasterSlaveMode = TIM_MASTERSLAVEMODE_DISABLE;
  if (HAL_TIMEx_MasterConfigSynchronization(&htim3, &sMasterConfig) != HAL_OK)
  {
    Error_Handler();
  }
  sConfigIC.ICPolarity = TIM_INPUTCHANNELPOLARITY_RISING;
  sConfigIC.ICSelection = TIM_ICSELECTION_DIRECTTI;
  sConfigIC.ICPrescaler = TIM_ICPSC_DIV1;
  sConfigIC.ICFilter = 0;
  if (HAL_TIM_IC_ConfigChannel(&htim3, &sConfigIC, TIM_CHANNEL_1) != HAL_OK)
  {
    Error_Handler();
  }

}

static void MX_TIM4_Init(void)
{

  TIM_ClockConfigTypeDef sClockSourceConfig = {0};
  TIM_MasterConfigTypeDef sMasterConfig = {0};
  TIM_IC_InitTypeDef sConfigIC = {0};

  htim4.Instance = TIM4;
  htim4.Init.Prescaler = 0;
  htim4.Init.CounterMode = TIM_COUNTERMODE_UP;
  htim4.Init.Period = 65535;
  htim4.Init.ClockDivision = TIM_CLOCKDIVISION_DIV1;
  htim4.Init.AutoReloadPreload = TIM_AUTORELOAD_PRELOAD_DISABLE;
  if (HAL_TIM_Base_Init(&htim4) != HAL_OK)
  {
    Error_Handler();
  }
  sClockSourceConfig.ClockSource = TIM_CLOCKSOURCE_INTERNAL;
  if (HAL_TIM_ConfigClockSource(&htim4, &sClockSourceConfig) != HAL_OK)
  {
    Error_Handler();
  }
  if (HAL_TIM_IC_Init(&htim4) != HAL_OK)
  {
    Error_Handler();
  }
  sMasterConfig.MasterOutputTrigger = TIM_TRGO_RESET;
  sMasterConfig.MasterSlaveMode = TIM_MASTERSLAVEMODE_DISABLE;
  if (HAL_TIMEx_MasterConfigSynchronization(&htim4, &sMasterConfig) != HAL_OK)
  {
    Error_Handler();
  }
  sConfigIC.ICPolarity = TIM_INPUTCHANNELPOLARITY_RISING;
  sConfigIC.ICSelection = TIM_ICSELECTION_DIRECTTI;
  sConfigIC.ICPrescaler = TIM_ICPSC_DIV1;
  sConfigIC.ICFilter = 0;
  if (HAL_TIM_IC_ConfigChannel(&htim4, &sConfigIC, TIM_CHANNEL_1) != HAL_OK)
  {
    Error_Handler();
  }
  if (HAL_TIM_IC_ConfigChannel(&htim4, &sConfigIC, TIM_CHANNEL_2) != HAL_OK)
  {
    Error_Handler();
  }

}

static void MX_TIM5_Init(void)
{

  TIM_ClockConfigTypeDef sClockSourceConfig = {0};
  TIM_MasterConfigTypeDef sMasterConfig = {0};
  TIM_IC_InitTypeDef sConfigIC = {0};

  htim5.Instance = TIM5;
  htim5.Init.Prescaler = 0;
  htim5.Init.CounterMode = TIM_COUNTERMODE_UP;
  htim5.Init.Period = 4294967295;
  htim5.Init.ClockDivision = TIM_CLOCKDIVISION_DIV1;
  htim5.Init.AutoReloadPreload = TIM_AUTORELOAD_PRELOAD_DISABLE;
  if (HAL_TIM_Base_Init(&htim5) != HAL_OK)
  {
    Error_Handler();
  }
  sClockSourceConfig.ClockSource = TIM_CLOCKSOURCE_INTERNAL;
  if (HAL_TIM_ConfigClockSource(&htim5, &sClockSourceConfig) != HAL_OK)
  {
    Error_Handler();
  }
  if (HAL_TIM_IC_Init(&htim5) != HAL_OK)
  {
    Error_Handler();
  }
  sMasterConfig.MasterOutputTrigger = TIM_TRGO_RESET;
  sMasterConfig.MasterSlaveMode = TIM_MASTERSLAVEMODE_DISABLE;
  if (HAL_TIMEx_MasterConfigSynchronization(&htim5, &sMasterConfig) != HAL_OK)
  {
    Error_Handler();
  }
  sConfigIC.ICPolarity = TIM_INPUTCHANNELPOLARITY_RISING;
  sConfigIC.ICSelection = TIM_ICSELECTION_DIRECTTI;
  sConfigIC.ICPrescaler = TIM_ICPSC_DIV1;
  sConfigIC.ICFilter = 0;
  if (HAL_TIM_IC_ConfigChannel(&htim5, &sConfigIC, TIM_CHANNEL_1) != HAL_OK)
  {
    Error_Handler();
  }

}

static void MX_TIM6_Init(void)
{

  TIM_MasterConfigTypeDef sMasterConfig = {0};

  htim6.Instance = TIM6;
  htim6.Init.Prescaler = 32;
  htim6.Init.CounterMode = TIM_COUNTERMODE_UP;
  htim6.Init.Period = 16;
  htim6.Init.AutoReloadPreload = TIM_AUTORELOAD_PRELOAD_DISABLE;
  if (HAL_TIM_Base_Init(&htim6) != HAL_OK)
  {
    Error_Handler();
  }
  sMasterConfig.MasterOutputTrigger = TIM_TRGO_UPDATE;
  sMasterConfig.MasterSlaveMode = TIM_MASTERSLAVEMODE_DISABLE;
  if (HAL_TIMEx_MasterConfigSynchronization(&htim6, &sMasterConfig) != HAL_OK)
  {
    Error_Handler();
  }

}

static void MX_TIM8_Init(void)
{

  TIM_MasterConfigTypeDef sMasterConfig = {0};
  TIM_IC_InitTypeDef sConfigIC = {0};

  htim8.Instance = TIM8;
  htim8.Init.Prescaler = 0;
  htim8.Init.CounterMode = TIM_COUNTERMODE_UP;
  htim8.Init.Period = 65535;
  htim8.Init.ClockDivision = TIM_CLOCKDIVISION_DIV1;
  htim8.Init.RepetitionCounter = 0;
  htim8.Init.AutoReloadPreload = TIM_AUTORELOAD_PRELOAD_DISABLE;
  if (HAL_TIM_IC_Init(&htim8) != HAL_OK)
  {
    Error_Handler();
  }
  sMasterConfig.MasterOutputTrigger = TIM_TRGO_RESET;
  sMasterConfig.MasterOutputTrigger2 = TIM_TRGO2_RESET;
  sMasterConfig.MasterSlaveMode = TIM_MASTERSLAVEMODE_DISABLE;
  if (HAL_TIMEx_MasterConfigSynchronization(&htim8, &sMasterConfig) != HAL_OK)
  {
    Error_Handler();
  }
  sConfigIC.ICPolarity = TIM_INPUTCHANNELPOLARITY_RISING;
  sConfigIC.ICSelection = TIM_ICSELECTION_DIRECTTI;
  sConfigIC.ICPrescaler = TIM_ICPSC_DIV1;
  sConfigIC.ICFilter = 0;
  if (HAL_TIM_IC_ConfigChannel(&htim8, &sConfigIC, TIM_CHANNEL_3) != HAL_OK)
  {
    Error_Handler();
  }

}

static void MX_TIM13_Init(void)
{

  htim13.Instance = TIM13;
  htim13.Init.Prescaler = 0;
  htim13.Init.CounterMode = TIM_COUNTERMODE_UP;
  htim13.Init.Period = 65535;
  htim13.Init.ClockDivision = TIM_CLOCKDIVISION_DIV1;
  htim13.Init.AutoReloadPreload = TIM_AUTORELOAD_PRELOAD_DISABLE;
  if (HAL_TIM_Base_Init(&htim13) != HAL_OK)
  {
    Error_Handler();
  }

}

static void MX_TIM14_Init(void)
{

  htim14.Instance = TIM14;
  htim14.Init.Prescaler = 0;
  htim14.Init.CounterMode = TIM_COUNTERMODE_UP;
  htim14.Init.Period = 65535;
  htim14.Init.ClockDivision = TIM_CLOCKDIVISION_DIV1;
  htim14.Init.AutoReloadPreload = TIM_AUTORELOAD_PRELOAD_DISABLE;
  if (HAL_TIM_Base_Init(&htim14) != HAL_OK)
  {
    Error_Handler();
  }

}

static void MX_TIM15_Init(void)
{

  TIM_MasterConfigTypeDef sMasterConfig = {0};
  TIM_IC_InitTypeDef sConfigIC = {0};

  htim15.Instance = TIM15;
  htim15.Init.Prescaler = 0;
  htim15.Init.CounterMode = TIM_COUNTERMODE_UP;
  htim15.Init.Period = 65535;
  htim15.Init.ClockDivision = TIM_CLOCKDIVISION_DIV1;
  htim15.Init.RepetitionCounter = 0;
  htim15.Init.AutoReloadPreload = TIM_AUTORELOAD_PRELOAD_DISABLE;
  if (HAL_TIM_IC_Init(&htim15) != HAL_OK)
  {
    Error_Handler();
  }
  sMasterConfig.MasterOutputTrigger = TIM_TRGO_RESET;
  sMasterConfig.MasterSlaveMode = TIM_MASTERSLAVEMODE_DISABLE;
  if (HAL_TIMEx_MasterConfigSynchronization(&htim15, &sMasterConfig) != HAL_OK)
  {
    Error_Handler();
  }
  sConfigIC.ICPolarity = TIM_INPUTCHANNELPOLARITY_RISING;
  sConfigIC.ICSelection = TIM_ICSELECTION_DIRECTTI;
  sConfigIC.ICPrescaler = TIM_ICPSC_DIV1;
  sConfigIC.ICFilter = 0;
  if (HAL_TIM_IC_ConfigChannel(&htim15, &sConfigIC, TIM_CHANNEL_2) != HAL_OK)
  {
    Error_Handler();
  }

}

static void MX_TIM16_Init(void)
{

  htim16.Instance = TIM16;
  htim16.Init.Prescaler = 0;
  htim16.Init.CounterMode = TIM_COUNTERMODE_UP;
  htim16.Init.Period = 65535;
  htim16.Init.ClockDivision = TIM_CLOCKDIVISION_DIV1;
  htim16.Init.RepetitionCounter = 0;
  htim16.Init.AutoReloadPreload = TIM_AUTORELOAD_PRELOAD_DISABLE;
  if (HAL_TIM_Base_Init(&htim16) != HAL_OK)
  {
    Error_Handler();
  }

}

static void MX_TIM17_Init(void)
{

  htim17.Instance = TIM17;
  htim17.Init.Prescaler = 0;
  htim17.Init.CounterMode = TIM_COUNTERMODE_UP;
  htim17.Init.Period = 65535;
  htim17.Init.ClockDivision = TIM_CLOCKDIVISION_DIV1;
  htim17.Init.RepetitionCounter = 0;
  htim17.Init.AutoReloadPreload = TIM_AUTORELOAD_PRELOAD_DISABLE;
  if (HAL_TIM_Base_Init(&htim17) != HAL_OK)
  {
    Error_Handler();
  }

}

static void MX_USART2_UART_Init(void)
{

  huart2.Instance = USART2;
  huart2.Init.BaudRate = 31250;
  huart2.Init.WordLength = UART_WORDLENGTH_8B;
  huart2.Init.StopBits = UART_STOPBITS_1;
  huart2.Init.Parity = UART_PARITY_NONE;
  huart2.Init.Mode = UART_MODE_TX_RX;
  huart2.Init.HwFlowCtl = UART_HWCONTROL_NONE;
  huart2.Init.OverSampling = UART_OVERSAMPLING_16;
  huart2.Init.OneBitSampling = UART_ONE_BIT_SAMPLE_DISABLE;
  huart2.Init.ClockPrescaler = UART_PRESCALER_DIV1;
  huart2.AdvancedInit.AdvFeatureInit = UART_ADVFEATURE_NO_INIT;
  if (HAL_UART_Init(&huart2) != HAL_OK)
  {
    Error_Handler();
  }
  if (HAL_UARTEx_SetTxFifoThreshold(&huart2, UART_TXFIFO_THRESHOLD_1_8) != HAL_OK)
  {
    Error_Handler();
  }
  if (HAL_UARTEx_SetRxFifoThreshold(&huart2, UART_RXFIFO_THRESHOLD_1_8) != HAL_OK)
  {
    Error_Handler();
  }
  if (HAL_UARTEx_DisableFifoMode(&huart2) != HAL_OK)
  {
    Error_Handler();
  }

}

static void MX_USART3_UART_Init(void)
{

  huart3.Instance = USART3;
  huart3.Init.BaudRate = 115200;
  huart3.Init.WordLength = UART_WORDLENGTH_8B;
  huart3.Init.StopBits = UART_STOPBITS_1;
  huart3.Init.Parity = UART_PARITY_NONE;
  huart3.Init.Mode = UART_MODE_TX_RX;
  huart3.Init.HwFlowCtl = UART_HWCONTROL_NONE;
  huart3.Init.OverSampling = UART_OVERSAMPLING_16;
  huart3.Init.OneBitSampling = UART_ONE_BIT_SAMPLE_DISABLE;
  huart3.Init.ClockPrescaler = UART_PRESCALER_DIV1;
  huart3.AdvancedInit.AdvFeatureInit = UART_ADVFEATURE_NO_INIT;
  if (HAL_UART_Init(&huart3) != HAL_OK)
  {
    Error_Handler();
  }
  if (HAL_UARTEx_SetTxFifoThreshold(&huart3, UART_TXFIFO_THRESHOLD_1_8) != HAL_OK)
  {
    Error_Handler();
  }
  if (HAL_UARTEx_SetRxFifoThreshold(&huart3, UART_RXFIFO_THRESHOLD_1_8) != HAL_OK)
  {
    Error_Handler();
  }
  if (HAL_UARTEx_DisableFifoMode(&huart3) != HAL_OK)
  {
    Error_Handler();
  }

}

static void MX_USB_OTG_HS_USB_Init(void)
{

}

static void MX_DMA_Init(void)
{

  /* DMA controller clock enable */
  __HAL_RCC_DMA1_CLK_ENABLE();

  /* DMA interrupt init */
  /* DMA1_Stream0_IRQn interrupt configuration */
  HAL_NVIC_SetPriority(DMA1_Stream0_IRQn, 0, 0);
  HAL_NVIC_EnableIRQ(DMA1_Stream0_IRQn);
  /* DMA1_Stream1_IRQn interrupt configuration */
  HAL_NVIC_SetPriority(DMA1_Stream1_IRQn, 0, 0);
  HAL_NVIC_EnableIRQ(DMA1_Stream1_IRQn);

}

static void MX_GPIO_Init(void)
{
  GPIO_InitTypeDef GPIO_InitStruct = {0};

  /* GPIO Ports Clock Enable */
  __HAL_RCC_GPIOE_CLK_ENABLE();
  __HAL_RCC_GPIOC_CLK_ENABLE();
  __HAL_RCC_GPIOF_CLK_ENABLE();
  __HAL_RCC_GPIOH_CLK_ENABLE();
  __HAL_RCC_GPIOA_CLK_ENABLE();
  __HAL_RCC_GPIOB_CLK_ENABLE();
  __HAL_RCC_GPIOG_CLK_ENABLE();
  __HAL_RCC_GPIOD_CLK_ENABLE();

  /*Configure GPIO pin Output Level */
  HAL_GPIO_WritePin(GPIOE, PE2_GPiO_LED0_Pin|PE3_GPiO_LED4_Pin|PE4_GPiO_LED1_Pin|PE5_GPiO_LED2_Pin
                          |GPIO_PIN_7|GPIO_PIN_8|GPIO_PIN_10|GPIO_PIN_12
                          |GPIO_PIN_13|GPIO_PIN_14|GPIO_PIN_15|GPIO_PIN_0
                          |LED_YELLOW_Pin, GPIO_PIN_RESET);

  /*Configure GPIO pin Output Level */
  HAL_GPIO_WritePin(GPIOF, PF0_Out_TX7_Pin|PF1_GPiO_LED7_Pin|PF2_GPIO_RST_MM_Pin|PF3_Out_TX0_Pin
                          |GPIO_PIN_4|GPIO_PIN_5|PF6_Out_TX1_Pin|PF7_Out_TX3_Pin
                          |PF8_Out_TX4_Pin|PF9_Out_TX2_Pin|GPIO_PIN_10|PF11_Out_TX6_Pin
                          |GPIO_PIN_12|GPIO_PIN_13|GPIO_PIN_14|GPIO_PIN_15, GPIO_PIN_RESET);

  /*Configure GPIO pin Output Level */
  HAL_GPIO_WritePin(GPIOC, GPIO_PIN_0|PC6_PROTO8_Pin|PC7_PROTO4_Pin|GPIO_PIN_9
                          |PC12_Out_TX5_Pin, GPIO_PIN_RESET);

  /*Configure GPIO pin Output Level */
  HAL_GPIO_WritePin(GPIOB, LED_GREEN_Pin|PB2_GPIO_XDCSN_MM_Pin|PB12_PROTO6_Pin|LED_RED_Pin
                          |PB15_PROTO7_Pin|GPIO_PIN_4|PB5_PROTO3_Pin|GPIO_PIN_6
                          |GPIO_PIN_7|PB8_PROTO9_Pin|PB9_PROTO10_Pin, GPIO_PIN_RESET);

  /*Configure GPIO pin Output Level */
  HAL_GPIO_WritePin(GPIOG, PG0_BUF_OE__Pin|PG1_Out_LED3_Pin|GPIO_PIN_3|GPIO_PIN_4
                          |GPIO_PIN_5|GPIO_PIN_6|GPIO_PIN_8|GPIO_PIN_9
                          |GPIO_PIN_10|GPIO_PIN_12|GPIO_PIN_14|GPIO_PIN_15, GPIO_PIN_RESET);

  /*Configure GPIO pin Output Level */
  HAL_GPIO_WritePin(GPIOD, GPIO_PIN_10|PD11_GPIO_MP3CSN_MM_Pin|GPIO_PIN_14|GPIO_PIN_15
                          |PD0_GPiO_LED6_Pin|PD1_GPiO_LED5_Pin|GPIO_PIN_2|GPIO_PIN_4
                          |GPIO_PIN_7, GPIO_PIN_RESET);

  /*Configure GPIO pin Output Level */
  HAL_GPIO_WritePin(GPIOA, GPIO_PIN_8|PA15_PROTO5_Pin, GPIO_PIN_RESET);

  /*Configure GPIO pins : PE2_GPiO_LED0_Pin PE3_GPiO_LED4_Pin PE4_GPiO_LED1_Pin PE5_GPiO_LED2_Pin
                           PE7 PE8 PE10 PE12
                           PE13 PE14 PE15 PE0
                           LED_YELLOW_Pin */
  GPIO_InitStruct.Pin = PE2_GPiO_LED0_Pin|PE3_GPiO_LED4_Pin|PE4_GPiO_LED1_Pin|PE5_GPiO_LED2_Pin
                          |GPIO_PIN_7|GPIO_PIN_8|GPIO_PIN_10|GPIO_PIN_12
                          |GPIO_PIN_13|GPIO_PIN_14|GPIO_PIN_15|GPIO_PIN_0
                          |LED_YELLOW_Pin;
  GPIO_InitStruct.Mode = GPIO_MODE_OUTPUT_PP;
  GPIO_InitStruct.Pull = GPIO_NOPULL;
  GPIO_InitStruct.Speed = GPIO_SPEED_FREQ_LOW;
  HAL_GPIO_Init(GPIOE, &GPIO_InitStruct);

  /*Configure GPIO pin : B1_Pin */
  GPIO_InitStruct.Pin = B1_Pin;
  GPIO_InitStruct.Mode = GPIO_MODE_INPUT;
  GPIO_InitStruct.Pull = GPIO_NOPULL;
  HAL_GPIO_Init(B1_GPIO_Port, &GPIO_InitStruct);

  /*Configure GPIO pins : PF0_Out_TX7_Pin PF1_GPiO_LED7_Pin PF2_GPIO_RST_MM_Pin PF3_Out_TX0_Pin
                           PF4 PF5 PF6_Out_TX1_Pin PF7_Out_TX3_Pin
                           PF8_Out_TX4_Pin PF9_Out_TX2_Pin PF10 PF11_Out_TX6_Pin
                           PF12 PF13 PF14 PF15 */
  GPIO_InitStruct.Pin = PF0_Out_TX7_Pin|PF1_GPiO_LED7_Pin|PF2_GPIO_RST_MM_Pin|PF3_Out_TX0_Pin
                          |GPIO_PIN_4|GPIO_PIN_5|PF6_Out_TX1_Pin|PF7_Out_TX3_Pin
                          |PF8_Out_TX4_Pin|PF9_Out_TX2_Pin|GPIO_PIN_10|PF11_Out_TX6_Pin
                          |GPIO_PIN_12|GPIO_PIN_13|GPIO_PIN_14|GPIO_PIN_15;
  GPIO_InitStruct.Mode = GPIO_MODE_OUTPUT_PP;
  GPIO_InitStruct.Pull = GPIO_NOPULL;
  GPIO_InitStruct.Speed = GPIO_SPEED_FREQ_LOW;
  HAL_GPIO_Init(GPIOF, &GPIO_InitStruct);

  /*Configure GPIO pins : PC0 PC6_PROTO8_Pin PC7_PROTO4_Pin PC9
                           PC12_Out_TX5_Pin */
  GPIO_InitStruct.Pin = GPIO_PIN_0|PC6_PROTO8_Pin|PC7_PROTO4_Pin|GPIO_PIN_9
                          |PC12_Out_TX5_Pin;
  GPIO_InitStruct.Mode = GPIO_MODE_OUTPUT_PP;
  GPIO_InitStruct.Pull = GPIO_NOPULL;
  GPIO_InitStruct.Speed = GPIO_SPEED_FREQ_LOW;
  HAL_GPIO_Init(GPIOC, &GPIO_InitStruct);

  /*Configure GPIO pins : LED_GREEN_Pin PB2_GPIO_XDCSN_MM_Pin PB12_PROTO6_Pin LED_RED_Pin
                           PB15_PROTO7_Pin PB4 PB5_PROTO3_Pin PB6
                           PB7 PB8_PROTO9_Pin PB9_PROTO10_Pin */
  GPIO_InitStruct.Pin = LED_GREEN_Pin|PB2_GPIO_XDCSN_MM_Pin|PB12_PROTO6_Pin|LED_RED_Pin
                          |PB15_PROTO7_Pin|GPIO_PIN_4|PB5_PROTO3_Pin|GPIO_PIN_6
                          |GPIO_PIN_7|PB8_PROTO9_Pin|PB9_PROTO10_Pin;
  GPIO_InitStruct.Mode = GPIO_MODE_OUTPUT_PP;
  GPIO_InitStruct.Pull = GPIO_NOPULL;
  GPIO_InitStruct.Speed = GPIO_SPEED_FREQ_LOW;
  HAL_GPIO_Init(GPIOB, &GPIO_InitStruct);

  /*Configure GPIO pins : PG0_BUF_OE__Pin PG1_Out_LED3_Pin PG3 PG4
                           PG5 PG6 PG8 PG9
                           PG10 PG12 PG14 PG15 */
  GPIO_InitStruct.Pin = PG0_BUF_OE__Pin|PG1_Out_LED3_Pin|GPIO_PIN_3|GPIO_PIN_4
                          |GPIO_PIN_5|GPIO_PIN_6|GPIO_PIN_8|GPIO_PIN_9
                          |GPIO_PIN_10|GPIO_PIN_12|GPIO_PIN_14|GPIO_PIN_15;
  GPIO_InitStruct.Mode = GPIO_MODE_OUTPUT_PP;
  GPIO_InitStruct.Pull = GPIO_NOPULL;
  GPIO_InitStruct.Speed = GPIO_SPEED_FREQ_LOW;
  HAL_GPIO_Init(GPIOG, &GPIO_InitStruct);

  /*Configure GPIO pin : PE11 */
  GPIO_InitStruct.Pin = GPIO_PIN_11;
  GPIO_InitStruct.Mode = GPIO_MODE_ANALOG;
  GPIO_InitStruct.Pull = GPIO_NOPULL;
  HAL_GPIO_Init(GPIOE, &GPIO_InitStruct);

  /*Configure GPIO pins : PD10 PD11_GPIO_MP3CSN_MM_Pin PD14 PD15
                           PD0_GPiO_LED6_Pin PD1_GPiO_LED5_Pin PD2 PD4
                           PD7 */
  GPIO_InitStruct.Pin = GPIO_PIN_10|PD11_GPIO_MP3CSN_MM_Pin|GPIO_PIN_14|GPIO_PIN_15
                          |PD0_GPiO_LED6_Pin|PD1_GPiO_LED5_Pin|GPIO_PIN_2|GPIO_PIN_4
                          |GPIO_PIN_7;
  GPIO_InitStruct.Mode = GPIO_MODE_OUTPUT_PP;
  GPIO_InitStruct.Pull = GPIO_NOPULL;
  GPIO_InitStruct.Speed = GPIO_SPEED_FREQ_LOW;
  HAL_GPIO_Init(GPIOD, &GPIO_InitStruct);

  /*Configure GPIO pin : PG2 */
  GPIO_InitStruct.Pin = GPIO_PIN_2;
  GPIO_InitStruct.Mode = GPIO_MODE_INPUT;
  GPIO_InitStruct.Pull = GPIO_NOPULL;
  HAL_GPIO_Init(GPIOG, &GPIO_InitStruct);

  /*Configure GPIO pin : USB_FS_OVCR_Pin */
  GPIO_InitStruct.Pin = USB_FS_OVCR_Pin;
  GPIO_InitStruct.Mode = GPIO_MODE_IT_RISING;
  GPIO_InitStruct.Pull = GPIO_NOPULL;
  HAL_GPIO_Init(USB_FS_OVCR_GPIO_Port, &GPIO_InitStruct);

  /*Configure GPIO pins : PA8 PA15_PROTO5_Pin */
  GPIO_InitStruct.Pin = GPIO_PIN_8|PA15_PROTO5_Pin;
  GPIO_InitStruct.Mode = GPIO_MODE_OUTPUT_PP;
  GPIO_InitStruct.Pull = GPIO_NOPULL;
  GPIO_InitStruct.Speed = GPIO_SPEED_FREQ_LOW;
  HAL_GPIO_Init(GPIOA, &GPIO_InitStruct);

  /*Configure GPIO pin : USB_FS_VBUS_Pin */
  GPIO_InitStruct.Pin = USB_FS_VBUS_Pin;
  GPIO_InitStruct.Mode = GPIO_MODE_INPUT;
  GPIO_InitStruct.Pull = GPIO_NOPULL;
  HAL_GPIO_Init(USB_FS_VBUS_GPIO_Port, &GPIO_InitStruct);

  /*Configure GPIO pin : USB_FS_ID_Pin */
  GPIO_InitStruct.Pin = USB_FS_ID_Pin;
  GPIO_InitStruct.Mode = GPIO_MODE_AF_PP;
  GPIO_InitStruct.Pull = GPIO_NOPULL;
  GPIO_InitStruct.Speed = GPIO_SPEED_FREQ_LOW;
  GPIO_InitStruct.Alternate = GPIO_AF10_OTG1_HS;
  HAL_GPIO_Init(USB_FS_ID_GPIO_Port, &GPIO_InitStruct);

}

void HAL_TIM_PeriodElapsedCallback(TIM_HandleTypeDef *htim)
{
  if (htim->Instance == TIM12) {
    HAL_IncTick();
  }
}

void Error_Handler(void)
{
  __disable_irq();
  while (1)
  {
  }
}
